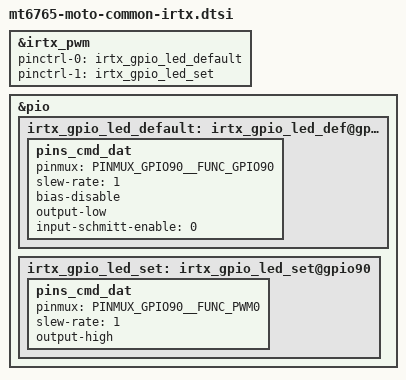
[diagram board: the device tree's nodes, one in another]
/* IRTX GPIO end */
&irtx_pwm {
	pinctrl-names = "irtx_gpio_led_default", "irtx_gpio_led_set";
	pinctrl-0 = <&irtx_gpio_led_default>;
	pinctrl-1 = <&irtx_gpio_led_set>;
	status = "okay";
};
&pio {
	irtx_gpio_led_default:irtx_gpio_led_def@gpio90 {
		pins_cmd_dat {
			pinmux = <PINMUX_GPIO90__FUNC_GPIO90>;
			slew-rate = <1>;
			bias-disable;
			output-low;
			input-schmitt-enable = <0>;
		};
	};

	irtx_gpio_led_set:irtx_gpio_led_set@gpio90 {
		pins_cmd_dat {
			pinmux = <PINMUX_GPIO90__FUNC_PWM0>;
			slew-rate = <1>;
			output-high;
		};
	};
};
/* IRTX GPIO Settings -End */
